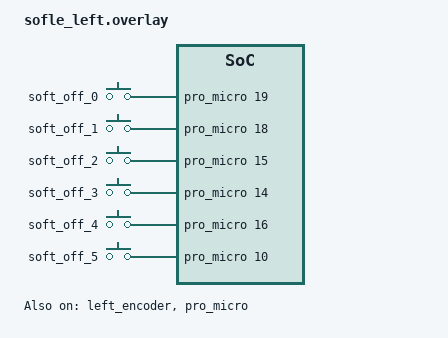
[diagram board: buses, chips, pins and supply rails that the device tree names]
/*
 * Copyright (c) 2020 Ryan Cross
 *
 * SPDX-License-Identifier: MIT
 */

#include "sofle.dtsi"

&kscan0 {
    col-gpios
        = <&pro_micro 19 GPIO_ACTIVE_HIGH>
        , <&pro_micro 18 GPIO_ACTIVE_HIGH>
        , <&pro_micro 15 GPIO_ACTIVE_HIGH>
        , <&pro_micro 14 GPIO_ACTIVE_HIGH>
        , <&pro_micro 16 GPIO_ACTIVE_HIGH>
        , <&pro_micro 10 GPIO_ACTIVE_HIGH>
        ;
};

&left_encoder {
    status = "okay";
};
&pro_micro { /* Ensure your GPIO controller node is identified correctly */
    status = "okay";
};

/ {
    behaviors {
        hw_soft_off: hw_soft_off {
            compatible = "zmk,behavior-soft-off";
            #binding-cells = <0>;
            hold-time-ms = <0>;
            split-peripheral-off-on-press; // This remains ambiguous but let's comment out if invalid
            /* If this property is invalid, remove or properly define as per docs */
        };
    };

    keys {
        compatible = "gpio-keys";

        /* Define each GPIO key as a child node with gpios property */

        soft_off_gpio_key0: soft_off_gpio_key0 {
            gpios = <&pro_micro 19 GPIO_ACTIVE_HIGH>;
            label = "soft_off_0";
        };

        soft_off_gpio_key1: soft_off_gpio_key1 {
            gpios = <&pro_micro 18 GPIO_ACTIVE_HIGH>;
            label = "soft_off_1";
        };

        soft_off_gpio_key2: soft_off_gpio_key2 {
            gpios = <&pro_micro 15 GPIO_ACTIVE_HIGH>;
            label = "soft_off_2";
        };

        soft_off_gpio_key3: soft_off_gpio_key3 {
            gpios = <&pro_micro 14 GPIO_ACTIVE_HIGH>;
            label = "soft_off_3";
        };

        soft_off_gpio_key4: soft_off_gpio_key4 {
            gpios = <&pro_micro 16 GPIO_ACTIVE_HIGH>;
            label = "soft_off_4";
        };

        soft_off_gpio_key5: soft_off_gpio_key5 {
            gpios = <&pro_micro 10 GPIO_ACTIVE_HIGH>;
            label = "soft_off_5";
        };
    };

    wakeup_scan: wakeup_scan {
        compatible = "zmk,kscan-gpio-direct";
        
        /* List all soft_off keys here */
        input-keys = <
            &soft_off_gpio_key0
            &soft_off_gpio_key1
            &soft_off_gpio_key2
            &soft_off_gpio_key3
            &soft_off_gpio_key4
            &soft_off_gpio_key5
        >;
        wakeup-source;
    };

    side_band_behavior_triggers: side_band_behavior_triggers {
        compatible = "zmk,kscan-sideband-behaviors";
        kscan = <&wakeup_scan>;
        auto-enable;
        wakeup-source;

        soft_off {
            column = <0>;
            row = <0>;
            bindings = <&hw_soft_off>;
        };
    };

    soft_off_wakers {
        compatible = "zmk,soft-off-wakeup-sources";
        wakeup-sources = <&wakeup_scan>;
    };
};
